# STM32MP13xx register map
File version: 1.5
CPU: CA7 r0p0, little endian, MPU, FPU, 4 interrupt priority bits
Registers are 32-bit, read-write, reset 0x0 unless marked. A register's access mark holds for its fields unless they carry their own. Offsets are from the block's base; [hi:lo] are bit positions; lines under a group give offsets from that group; {n}, {i} and the like mark numbered series; 'fields as' and 'values as' point back to an identical list.

## TSC
Base 0x5000B000
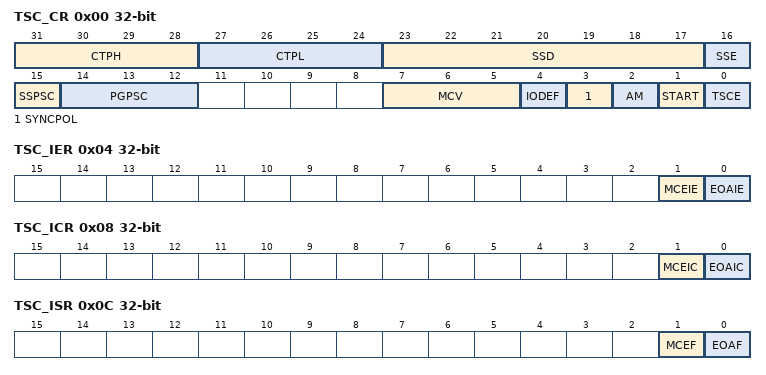
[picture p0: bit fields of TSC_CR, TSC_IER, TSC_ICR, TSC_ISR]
0x00 TSC_CR
  [31:28] CTPH — Charge transfer pulse high These bits are set and cleared by software. They define the duration of the high state of the charge transfer pulse (charge of CX). ... Note: These bits must not be modified when an acquisition is ongoing.
    0=1x tPGCLK; 1=2x tPGCLK; 15=16x tPGCLK
  [27:24] CTPL — Charge transfer pulse low These bits are set and cleared by software. They define the duration of the low state of the charge transfer pulse (transfer of charge from CX to CS). ... Note: These bits must not be modified when an acquisition is ongoing. Note: Some configurations are forbidden. Refer to the acquisition sequence for details.
    0=1x tPGCLK; 1=2x tPGCLK; 15=16x tPGCLK
  [23:17] SSD — Spread spectrum deviation These bits are set and cleared by software. They define the spread spectrum deviation which consists in adding a variable number of periods of the SSCLK clock to the charge transfer pulse high state. ... Note: These bits must not be modified when an acquisition is ongoing.
    0=1x tSSCLK; 1=2x tSSCLK; 127=128x tSSCLK
  [16] SSE — Spread spectrum enable This bit is set and cleared by software to enable/disable the spread spectrum feature. Note: This bit must not be modified when an acquisition is ongoing.
    0=Spread spectrum disabled; 1=Spread spectrum enabled
  [15] SSPSC — Spread spectrum prescaler This bit is set and cleared by software. It selects the AHB clock divider used to generate the spread spectrum clock (SSCLK). Note: This bit must not be modified when an acquisition is ongoing.
    0=fHCLK; 1=fHCLK /2
  [14:12] PGPSC — Pulse generator prescaler These bits are set and cleared by software.They select the AHB clock divider used to generate the pulse generator clock (PGCLK). Note: These bits must not be modified when an acquisition is ongoing. Note: Some configurations are forbidden. Refer to the acquisition sequence for details.
    0=fHCLK; 1=fHCLK /2; 2=fHCLK /4; 3=fHCLK /8; 4=fHCLK /16; 5=fHCLK /32; 6=fHCLK /64; 7=fHCLK /128
  [7:5] MCV — Max count value These bits are set and cleared by software. They define the maximum number of charge transfer pulses that can be generated before a max count error is generated. Note: These bits must not be modified when an acquisition is ongoing.
    0=255; 1=511; 2=1023; 3=2047; 4=4095; 5=8191; 6=16383
  [4] IODEF — I/O Default mode This bit is set and cleared by software. It defines the configuration of all the TSC I/Os when there is no ongoing acquisition. When there is an ongoing acquisition, it defines the configuration of all unused I/Os (not defined as sampling capacitor I/O or as channel I/O). Note: This bit must not be modified when an acquisition is ongoing.
    0=I/Os are forced to output push-pull low; 1=I/Os are in input floating
  [3] SYNCPOL — Synchronization pin polarity This bit is set and cleared by software to select the polarity of the synchronization input pin.
    0=Falling edge only; 1=Rising edge and high level
  [2] AM — Acquisition mode This bit is set and cleared by software to select the acquisition mode. Note: This bit must not be modified when an acquisition is ongoing.
    0=Normal acquisition mode (acquisition starts as soon as START bit is set); 1=Synchronized acquisition mode (acquisition starts if START bit is set and when the selected signal is detected on the SYNC input pin)
  [1] START — Start a new acquisition This bit is set by software to start a new acquisition. It is cleared by hardware as soon as the acquisition is complete or by software to cancel the ongoing acquisition.
    0=Acquisition not started; 1=Start a new acquisition
  [0] TSCE — Touch sensing controller enable This bit is set and cleared by software to enable/disable the touch sensing controller. Note: When the touch sensing controller is disabled, TSC registers settings have no effect.
    0=Touch sensing controller disabled; 1=Touch sensing controller enabled
0x04 TSC_IER
  [1] MCEIE — Max count error interrupt enable This bit is set and cleared by software to enable/disable the max count error interrupt.
    0=Max count error interrupt disabled; 1=Max count error interrupt enabled
  [0] EOAIE — End of acquisition interrupt enable This bit is set and cleared by software to enable/disable the end of acquisition interrupt.
    0=End of acquisition interrupt disabled; 1=End of acquisition interrupt enabled
0x08 TSC_ICR
  [1] MCEIC — Max count error interrupt clear This bit is set by software to clear the max count error flag and it is cleared by hardware when the flag is reset. Writing a '0â has no effect.
    0=No effect; 1=Clears the corresponding MCEF of the TSC_ISR register
  [0] EOAIC — End of acquisition interrupt clear This bit is set by software to clear the end of acquisition flag and it is cleared by hardware when the flag is reset. Writing a '0â has no effect.
    0=No effect; 1=Clears the corresponding EOAF of the TSC_ISR register
0x0C TSC_ISR ro
  [1] MCEF — Max count error flag This bit is set by hardware as soon as an analog I/O group counter reaches the max count value specified. It is cleared by software writing 1 to the bit MCEIC of the TSC_ICR register.
    0=No max count error (MCE) detected; 1=Max count error (MCE) detected
  [0] EOAF — End of acquisition flag This bit is set by hardware when the acquisition of all enabled group is complete (all GxS bits of all enabled analog I/O groups are set or when a max count error is detected). It is cleared by software writing 1 to the bit EOAIC of the TSC_ICR register.
    0=Acquisition is ongoing or not started; 1=Acquisition is complete
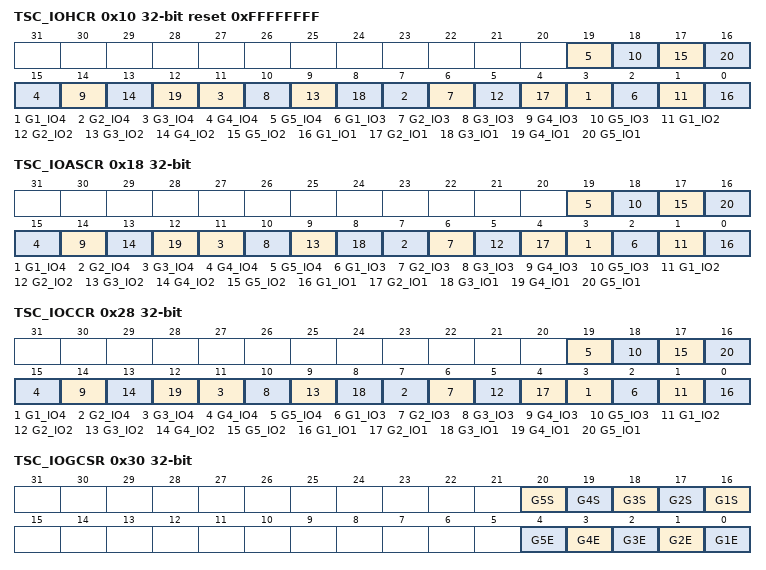
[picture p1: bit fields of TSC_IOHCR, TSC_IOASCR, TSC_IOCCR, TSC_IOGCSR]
0x10 TSC_IOHCR reset 0xFFFFFFFF
  [4n-1] G{n}_IO4 (n=1..5), [4n-2] G{n}_IO3 (n=1..5), [4n-3] G{n}_IO2 (n=1..5), [4n-4] G{n}_IO1 (n=1..5)
0x18 TSC_IOASCR
  fields as TSC_IOHCR
0x28 TSC_IOCCR
  fields as TSC_IOHCR
0x30 TSC_IOGCSR access per field
  [n+15] G{n}S ro (n=1..5), [n-1] G{n}E rw (n=1..5)
{0x30+4i} TSC_IOG{i}CR ro (i=1..4)
  [13:0] CNT — Counter value
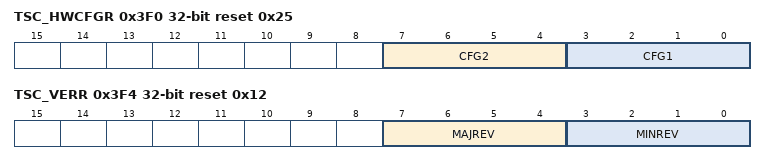
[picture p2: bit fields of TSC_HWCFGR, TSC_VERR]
0x3F0 TSC_HWCFGR ro reset 0x25
  [7:4] CFG2 — TSC hardware configuration 2 These bits return the TSP CFG2[3:0] configuration. CFG2[3:0] = dt_duration = 0x2 (dead time duration).
  [3:0] CFG1 — TSC hardware configuration 1 These bits return the TSP CFG1[3:0] configuration. CFG1[3:0] = group_size = 0x5 (group size).
0x3F4 TSC_VERR ro reset 0x12
  [7:4] MAJREV — Major revision These bits return the TSC major revision. MAJREV[3:0] = 0x1
  [3:0] MINREV — Minor revision These bits return the TSC minor revision. MINREV[3:0] = 0x2
0x3F8 TSC_IDR ro reset 0x110041
  [31:0] ID — TSC identifier These bits return the TSC identifier. ID[31:0] = 0x00110041
0x3FC TSC_SIDR ro reset 0xA3C5DD01
  [31:0] SID — TSC size identification These bits return the size of the memory region allocated to the TSC registers. SID[31:0] = 0xA3C5DD01
